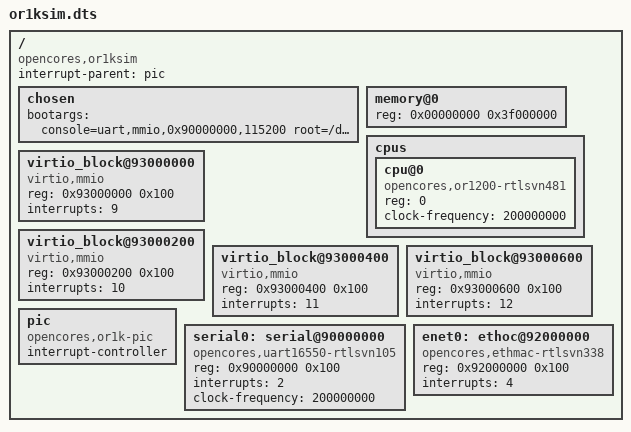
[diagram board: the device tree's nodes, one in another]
/dts-v1/;
/ {
	compatible = "opencores,or1ksim";
	#address-cells = <1>;
	#size-cells = <1>;
	interrupt-parent = <&pic>;

	chosen {
		bootargs = "console=uart,mmio,0x90000000,115200 root=/dev/vda";
	};

	memory@0 {
		device_type = "memory";
		reg = <0x00000000 0x3f000000>;
	};

	cpus {
		#address-cells = <1>;
		#size-cells = <0>;
		cpu@0 {
			compatible = "opencores,or1200-rtlsvn481";
			reg = <0>;
			clock-frequency = <200000000>;
		};
	};

	virtio_block@93000000 {
		compatible = "virtio,mmio";
		reg = <0x93000000 0x100>;
		interrupts = <9>;
	};

	virtio_block@93000200 {
		compatible = "virtio,mmio";
		reg = <0x93000200 0x100>;
		interrupts = <10>;
	};

	virtio_block@93000400 {
		compatible = "virtio,mmio";
		reg = <0x93000400 0x100>;
		interrupts = <11>;
	};

	virtio_block@93000600 {
		compatible = "virtio,mmio";
		reg = <0x93000600 0x100>;
		interrupts = <12>;
	};

	/*
	 * OR1K PIC is built into CPU and accessed via special purpose
	 * registers.  It is not addressable and, hence, has no 'reg'
	 * property.
	 */
	pic: pic {
		compatible = "opencores,or1k-pic";
		#interrupt-cells = <1>;
		interrupt-controller;
	};

	serial0: serial@90000000 {
		compatible = "opencores,uart16550-rtlsvn105", "ns16550a";
		reg = <0x90000000 0x100>;
		interrupts = <2>;
		clock-frequency = <200000000>;
	};

	enet0: ethoc@92000000 {
		compatible = "opencores,ethmac-rtlsvn338";
		reg = <0x92000000 0x100>;
		interrupts = <4>;
	};

};
